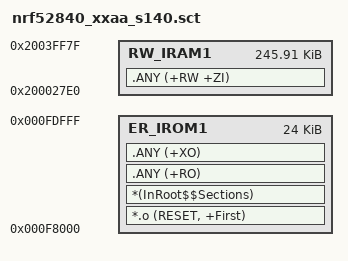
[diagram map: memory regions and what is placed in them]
; *************************************************************
; *** Scatter-Loading Description File generated by uVision ***
; *************************************************************

LR_IROM1 0x000F8000 0x00006000  {    ; load region size_region
  ER_IROM1 0x000F8000 0x00006000  {  ; load address = execution address
   *.o (RESET, +First)
   *(InRoot$$Sections)
   .ANY (+RO)
   .ANY (+XO)
  }
  RW_IRAM1 0x200027E0 0x0003D7A0  {  ; RW data
   .ANY (+RW +ZI)
  }
}

